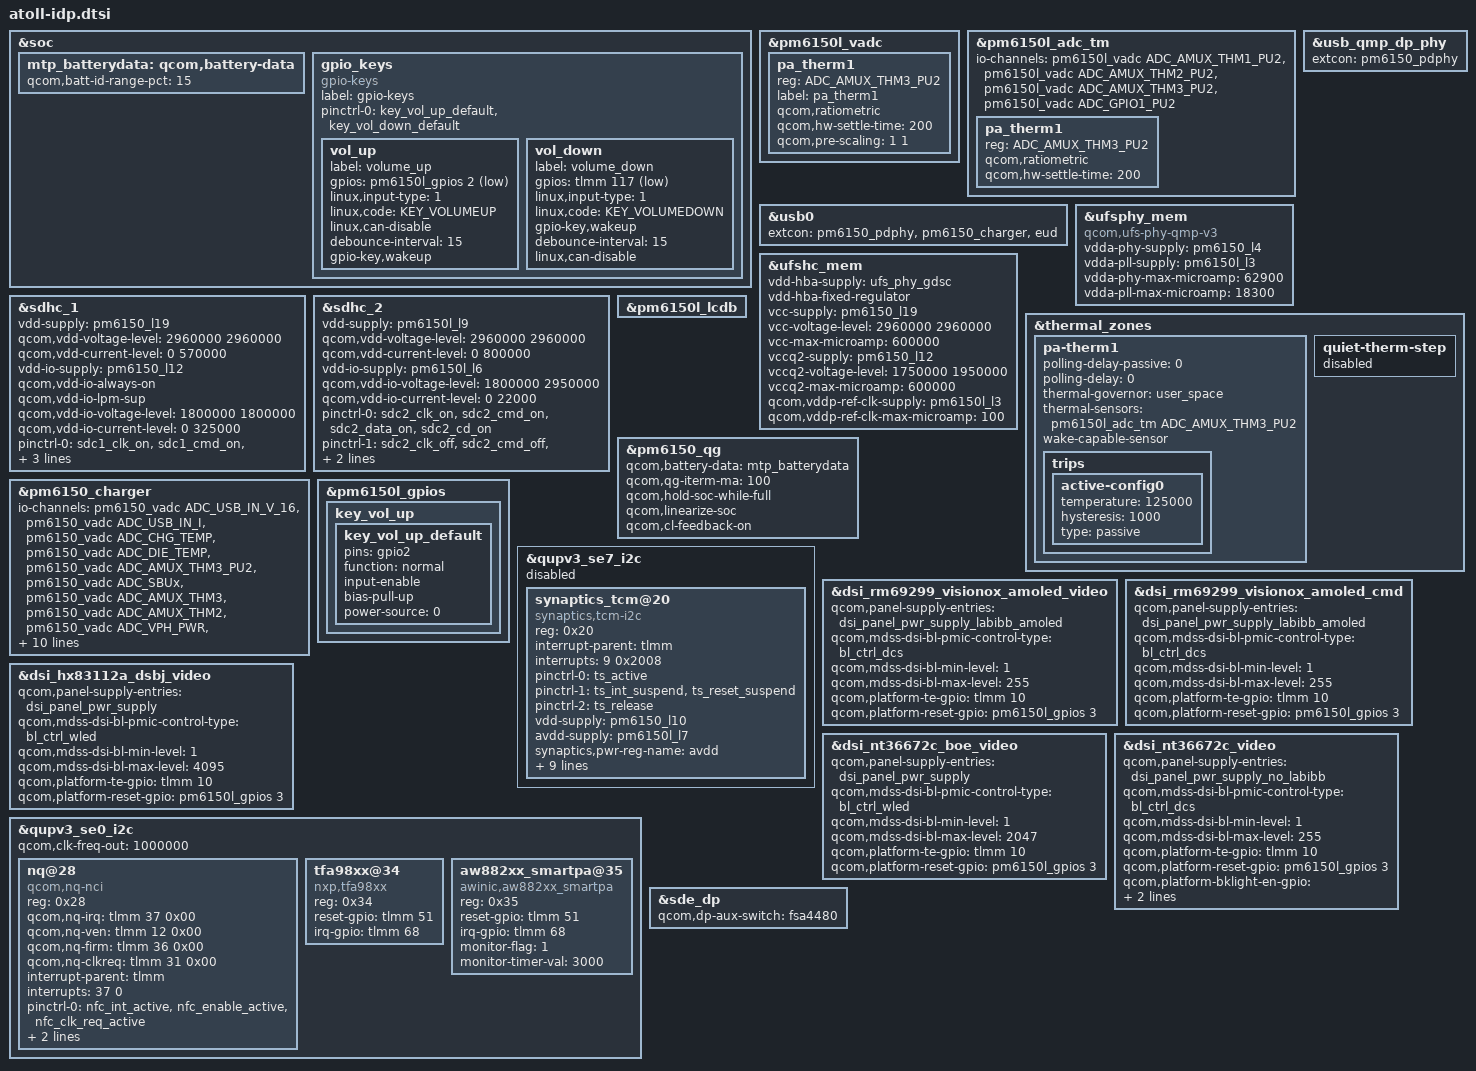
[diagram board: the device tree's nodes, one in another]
/* Copyright (c) 2019, The Linux Foundation. All rights reserved.
 *
 * This program is free software; you can redistribute it and/or modify
 * it under the terms of the GNU General Public License version 2 and
 * only version 2 as published by the Free Software Foundation.
 *
 * This program is distributed in the hope that it will be useful,
 * but WITHOUT ANY WARRANTY; without even the implied warranty of
 * MERCHANTABILITY or FITNESS FOR A PARTICULAR PURPOSE.  See the
 * GNU General Public License for more details.
 */

#include <dt-bindings/gpio/gpio.h>
#include <dt-bindings/pinctrl/qcom,pmic-gpio.h>
#include <dt-bindings/iio/qcom,spmi-vadc.h>
#include <dt-bindings/input/input.h>
#include "atoll-sde-display.dtsi"
#include "atoll-camera-sensor-idp.dtsi"
#include "sdmmagpie-thermal-overlay.dtsi"

&soc {
	mtp_batterydata: qcom,battery-data {
		qcom,batt-id-range-pct = <15>;
		#include "qg-batterydata-alium-3600mah.dtsi"
	};
};

&pm6150l_vadc {
	pa_therm1 {
		reg = <ADC_AMUX_THM3_PU2>;
		label = "pa_therm1";
		qcom,ratiometric;
		qcom,hw-settle-time = <200>;
		qcom,pre-scaling = <1 1>;
	};
};

&pm6150l_adc_tm {
	io-channels = <&pm6150l_vadc ADC_AMUX_THM1_PU2>,
			<&pm6150l_vadc ADC_AMUX_THM2_PU2>,
			<&pm6150l_vadc ADC_AMUX_THM3_PU2>,
			<&pm6150l_vadc ADC_GPIO1_PU2>;

	pa_therm1 {
		reg = <ADC_AMUX_THM3_PU2>;
		qcom,ratiometric;
		qcom,hw-settle-time = <200>;
	};
};

&usb0 {
	extcon = <&pm6150_pdphy>, <&pm6150_charger>, <&eud>;
};

&usb_qmp_dp_phy {
	extcon = <&pm6150_pdphy>;
};

&ufsphy_mem {
	compatible = "qcom,ufs-phy-qmp-v3";

	vdda-phy-supply = <&pm6150_l4>; /* 0.9v */
	vdda-pll-supply = <&pm6150l_l3>; /* 1.2v */
	vdda-phy-max-microamp = <62900>;
	vdda-pll-max-microamp = <18300>;

	status = "ok";
};

&ufshc_mem {
	vdd-hba-supply = <&ufs_phy_gdsc>;
	vdd-hba-fixed-regulator;
	vcc-supply = <&pm6150_l19>;
	vcc-voltage-level = <2960000 2960000>;
	vcc-max-microamp = <600000>;
	vccq2-supply = <&pm6150_l12>;
	vccq2-voltage-level = <1750000 1950000>;
	vccq2-max-microamp = <600000>;

	qcom,vddp-ref-clk-supply = <&pm6150l_l3>; /* PX10 */
	qcom,vddp-ref-clk-max-microamp = <100>;

	status = "ok";
};

&sdhc_1 {
	vdd-supply = <&pm6150_l19>;
	qcom,vdd-voltage-level = <2960000 2960000>;
	qcom,vdd-current-level = <0 570000>;

	vdd-io-supply = <&pm6150_l12>;
	qcom,vdd-io-always-on;
	qcom,vdd-io-lpm-sup;
	qcom,vdd-io-voltage-level = <1800000 1800000>;
	qcom,vdd-io-current-level = <0 325000>;

	pinctrl-names = "active", "sleep";
	pinctrl-0 = <&sdc1_clk_on &sdc1_cmd_on &sdc1_data_on &sdc1_rclk_on>;
	pinctrl-1 = <&sdc1_clk_off &sdc1_cmd_off &sdc1_data_off &sdc1_rclk_off>;

	status = "ok";
};

&sdhc_2 {
	vdd-supply = <&pm6150l_l9>;
	qcom,vdd-voltage-level = <2960000 2960000>;
	qcom,vdd-current-level = <0 800000>;

	vdd-io-supply = <&pm6150l_l6>;
	qcom,vdd-io-voltage-level = <1800000 2950000>;
	qcom,vdd-io-current-level = <0 22000>;

	pinctrl-names = "active", "sleep";
	pinctrl-0 = <&sdc2_clk_on  &sdc2_cmd_on &sdc2_data_on &sdc2_cd_on>;
	pinctrl-1 = <&sdc2_clk_off &sdc2_cmd_off &sdc2_data_off &sdc2_cd_off>;

/*#ifndef ODM_LQ_EDIT*/
/*liujiawei@ODM_LQ@BSP.Tcard,2019/10/09,modified for bring up Tcard hot-plug*/
	//cd-gpios = <&tlmm 69 GPIO_ACTIVE_LOW>;
/*#else*/
	cd-gpios = <&tlmm 69 GPIO_ACTIVE_HIGH>;
/*#endif*/

	status = "ok";
};

&thermal_zones {
	pa-therm1 {
		polling-delay-passive = <0>;
		polling-delay = <0>;
		thermal-governor = "user_space";
		thermal-sensors = <&pm6150l_adc_tm ADC_AMUX_THM3_PU2>;
		wake-capable-sensor;
		trips {
			active-config0 {
				temperature = <125000>;
				hysteresis = <1000>;
				type = "passive";
			};
		};
	};

	quiet-therm-step {
		status = "disabled";
	};
};
/*#ifndef ODM_LQ_EDIT*/
/*zengjianxiong@ODM_LQ@Multimedia.Dispaly,2019/10/03,modified for bring up LCD*/
/*&pm6150a_amoled {
	status = "ok";
};*/
/*else ODM_LQ_EDIT*/
&pm6150l_lcdb {
    status = "ok";
};
/*#endif ODM_LQ_EDIT*/

&pm6150_qg {
	qcom,battery-data = <&mtp_batterydata>;
	qcom,qg-iterm-ma = <100>;
	qcom,hold-soc-while-full;
	qcom,linearize-soc;
	qcom,cl-feedback-on;
};

&pm6150_charger {
	io-channels = <&pm6150_vadc ADC_USB_IN_V_16>,
		      <&pm6150_vadc ADC_USB_IN_I>,
		      <&pm6150_vadc ADC_CHG_TEMP>,
		      <&pm6150_vadc ADC_DIE_TEMP>,
		      <&pm6150_vadc ADC_AMUX_THM3_PU2>,
		      <&pm6150_vadc ADC_SBUx>,
//#ifdef VENDOR_EDIT
/* Yichun.Chen  PSW.BSP.CHG  2019-04-22  for usbtemp */
		      <&pm6150_vadc ADC_AMUX_THM3>,
		      <&pm6150_vadc ADC_AMUX_THM2>,
//#endif
//#ifndef VENDOR_EDIT
/* Yichun.Chen  PSW.BSP.CHG  2019-04-13  for read chargerid */
//		      <&pm6150_vadc ADC_VPH_PWR>;
//#else
		      <&pm6150_vadc ADC_VPH_PWR>,
		      <&pm6150l_vadc ADC_GPIO2>;
//#endif
	io-channel-names = "usb_in_voltage",
			   "usb_in_current",
			   "chg_temp",
			   "die_temp",
			   "conn_temp",
			   "sbux_res",
//#ifdef VENDOR_EDIT
/* Yichun.Chen  PSW.BSP.CHG  2019-04-22  for usbtemp */
			   "usb_temp1",
			   "usb_temp2",
//#endif
//#ifndef VENDOR_EDIT
/* Yichun.Chen  PSW.BSP.CHG  2019-04-13  for read chargerid */
//			   "vph_voltage";
//#else
			   "vph_voltage",
			   "chgid_voltage";
//#endif
	qcom,battery-data = <&mtp_batterydata>;
//#ifndef VENDOR_EDIT
/* Yichun.Chen  PSW.BSP.CHG  2019-05-05  for charge */
//	qcom,auto-recharge-soc = <98>;
//	qcom,step-charging-enable;
//	qcom,sw-jeita-enable;
//	qcom,fcc-stepping-enable;
//	qcom,suspend-input-on-debug-batt;
//	qcom,sec-charger-config = <3>;
//	qcom,thermal-mitigation = <4200000 3500000 3000000
//			2500000 2000000 1500000 1000000 500000>;
//#endif
	dpdm-supply = <&qusb_phy0>;
	qcom,charger-temp-max = <800>;
	qcom,smb-temp-max = <800>;
	qcom,fcc-step-delay-ms = <100>;
	qcom,fcc-step-size-ua = <100000>;
	qcom,disable-sw-thermal-regulation;
	qcom,disable-fcc-restriction;
	qcom,smb-internal-pull-kohm = <0>;
};

&pm6150l_gpios {
	key_vol_up {
		key_vol_up_default: key_vol_up_default {
			pins = "gpio2";
			function = "normal";
			input-enable;
			bias-pull-up;
			power-source = <0>;
		};
	};
};

&soc {
	gpio_keys {
		compatible = "gpio-keys";
		label = "gpio-keys";

		pinctrl-names = "default";
/*#ifndef ODM_LQ_EDIT*/
/*Hongbin.Chen@ODM_LQ@BSP.Key,2019/10/08 Modify for config volum down key*/
/*		pinctrl-0 = <&key_vol_up_default>;*/
/*#else*/
		pinctrl-0 = <&key_vol_up_default
			&key_vol_down_default>;
/*#endif  ODM_LQ_EDIT*/

		vol_up {
			label = "volume_up";
			gpios = <&pm6150l_gpios 2 GPIO_ACTIVE_LOW>;
			linux,input-type = <1>;
			linux,code = <KEY_VOLUMEUP>;
			linux,can-disable;
			debounce-interval = <15>;
			gpio-key,wakeup;
		};
/*#ifdef ODM_LQ_EDIT*/
/*Hongbin.Chen@ODM_LQ@BSP.Key,2019/10/08 Modify for config volum down key*/
		vol_down {
			label = "volume_down";
			gpios = <&tlmm 117 GPIO_ACTIVE_LOW>;
			linux,input-type = <1>;
			linux,code = <KEY_VOLUMEDOWN>;
			gpio-key,wakeup;
			debounce-interval = <15>;
			linux,can-disable;
		};
/*#endif  ODM_LQ_EDIT*/
	};
};

&qupv3_se7_i2c {
/*#ifndef ODM_LQ_EDIT*/
/*liujiawei@ODM_LQ@BSP.CHG,2019/10/08,modified for disable qupv3_se7_i2c*/
//	status = "ok";
/*#else*/
	status = "disabled";
/*#endif*/
	synaptics_tcm@20 {
		compatible = "synaptics,tcm-i2c";
		reg = <0x20>;
		interrupt-parent = <&tlmm>;
		interrupts = <9 0x2008>;
		pinctrl-names = "pmx_ts_active","pmx_ts_suspend",
			"pmx_ts_release";
		pinctrl-0 = <&ts_active>;
		pinctrl-1 = <&ts_int_suspend &ts_reset_suspend>;
		pinctrl-2 = <&ts_release>;
		vdd-supply = <&pm6150_l10>;
		avdd-supply = <&pm6150l_l7>;
		synaptics,pwr-reg-name = "avdd";
		synaptics,bus-reg-name = "vdd";
		synaptics,irq-gpio = <&tlmm 9 0x2008>;
		synaptics,irq-on-state = <0>;
		synaptics,reset-gpio = <&tlmm 8 0x00>;
		synaptics,reset-on-state = <0>;
		synaptics,reset-active-ms = <20>;
		synaptics,reset-delay-ms = <200>;
		synaptics,power-delay-ms = <200>;
		synaptics,ubl-i2c-addr = <0x20>;
	};
};

&dsi_rm69299_visionox_amoled_video {
	qcom,panel-supply-entries = <&dsi_panel_pwr_supply_labibb_amoled>;
	qcom,mdss-dsi-bl-pmic-control-type = "bl_ctrl_dcs";
	qcom,mdss-dsi-bl-min-level = <1>;
	qcom,mdss-dsi-bl-max-level = <255>;
	qcom,platform-te-gpio = <&tlmm 10 0>;
	qcom,platform-reset-gpio = <&pm6150l_gpios 3 0>;
};

&dsi_rm69299_visionox_amoled_cmd {
	qcom,panel-supply-entries = <&dsi_panel_pwr_supply_labibb_amoled>;
	qcom,mdss-dsi-bl-pmic-control-type = "bl_ctrl_dcs";
	qcom,mdss-dsi-bl-min-level = <1>;
	qcom,mdss-dsi-bl-max-level = <255>;
	qcom,platform-te-gpio = <&tlmm 10 0>;
	qcom,platform-reset-gpio = <&pm6150l_gpios 3 0>;
};

/*#ifdef ODM_LQ_EDIT*/
/*zengjianxiong@ODM_LQ@Multimedia.Dispaly,2019/10/03,modified for bring up LCD*/
&dsi_hx83112a_dsbj_video {
	qcom,panel-supply-entries = <&dsi_panel_pwr_supply>;
	qcom,mdss-dsi-bl-pmic-control-type = "bl_ctrl_wled";
	qcom,mdss-dsi-bl-min-level = <1>;
	qcom,mdss-dsi-bl-max-level = <4095>;
	qcom,platform-te-gpio = <&tlmm 10 0>;
	qcom,platform-reset-gpio = <&pm6150l_gpios 3 0>;
};
/*#endif ODM_LQ_EDIT*/

/*#ifdef ODM_LQ_EDIT*/
/*zengjianxiong@ODM_LQ@Multimedia.Dispaly,2019/10/25,add for bringup C-PHY LCD*/
&dsi_nt36672c_boe_video {
	qcom,panel-supply-entries = <&dsi_panel_pwr_supply>;
	qcom,mdss-dsi-bl-pmic-control-type = "bl_ctrl_wled";
	qcom,mdss-dsi-bl-min-level = <1>;
	qcom,mdss-dsi-bl-max-level = <2047>;
	qcom,platform-te-gpio = <&tlmm 10 0>;
	qcom,platform-reset-gpio = <&pm6150l_gpios 3 0>;
};
/*#endif ODM_LQ_EDIT*/

&dsi_nt36672c_video {
	qcom,panel-supply-entries = <&dsi_panel_pwr_supply_no_labibb>;
	qcom,mdss-dsi-bl-pmic-control-type = "bl_ctrl_dcs";
	qcom,mdss-dsi-bl-min-level = <1>;
	qcom,mdss-dsi-bl-max-level = <255>;
	qcom,platform-te-gpio = <&tlmm 10 0>;
	qcom,platform-reset-gpio = <&pm6150l_gpios 3 0>;
	qcom,platform-bklight-en-gpio = <&pm6150l_gpios 10 0>;
	qcom,platform-en-gpio = <&pm6150l_gpios 4 0>;
};

&qupv3_se0_i2c {
	status = "ok";
	qcom,clk-freq-out = <1000000>;
	#address-cells = <1>;
	#size-cells = <0>;
	nq@28 {
		compatible = "qcom,nq-nci";
		reg = <0x28>;
		qcom,nq-irq = <&tlmm 37 0x00>;
		qcom,nq-ven = <&tlmm 12 0x00>;
		qcom,nq-firm = <&tlmm 36 0x00>;
		qcom,nq-clkreq = <&tlmm 31 0x00>;
		interrupt-parent = <&tlmm>;
		interrupts = <37 0>;
		interrupt-names = "nfc_irq";
		pinctrl-names = "nfc_active", "nfc_suspend";
		pinctrl-0 = <&nfc_int_active &nfc_enable_active
				&nfc_clk_req_active>;
		pinctrl-1 = <&nfc_int_suspend &nfc_enable_suspend
				&nfc_clk_req_suspend>;
	};

	/*#ifdef ODM_LQ_EDIT*/
	/*shentaotao@ODM_LQ@Multimedia.Audio,2019/10/08,modified for audio bringup*/
	/* NXP TFA9874 smartPA start */
	tfa98xx@34 {
		compatible = "nxp,tfa98xx";
		reg = <0x34>;
		reset-gpio = <&tlmm 51 0>;
		irq-gpio = <&tlmm 68 0>;
	};
	/* NXP TFA9874 smartPA end */

	/* AWINIC AW882XX Smart PA start*/
	aw882xx_smartpa@35 {
		compatible = "awinic,aw882xx_smartpa";
		reg = <0x35>;
		reset-gpio = <&tlmm 51 0>;
		irq-gpio = <&tlmm 68 0x2008>;
		monitor-flag = <1>;
		monitor-timer-val = <3000>;
		status = "okay";
	};
	/* AWINIC AW882XX Smart PA end */
	/*#endif ODM_LQ_EDIT*/
};

&sde_dp{
	qcom,dp-aux-switch = <&fsa4480>;
};

//#ifdef VENDOR_EDIT
///* Yichun.Chen  PSW.BSP.CHG  2019-05-30  oppo charge edit dts */
#include "oppo-charge.dtsi"
//#endif

